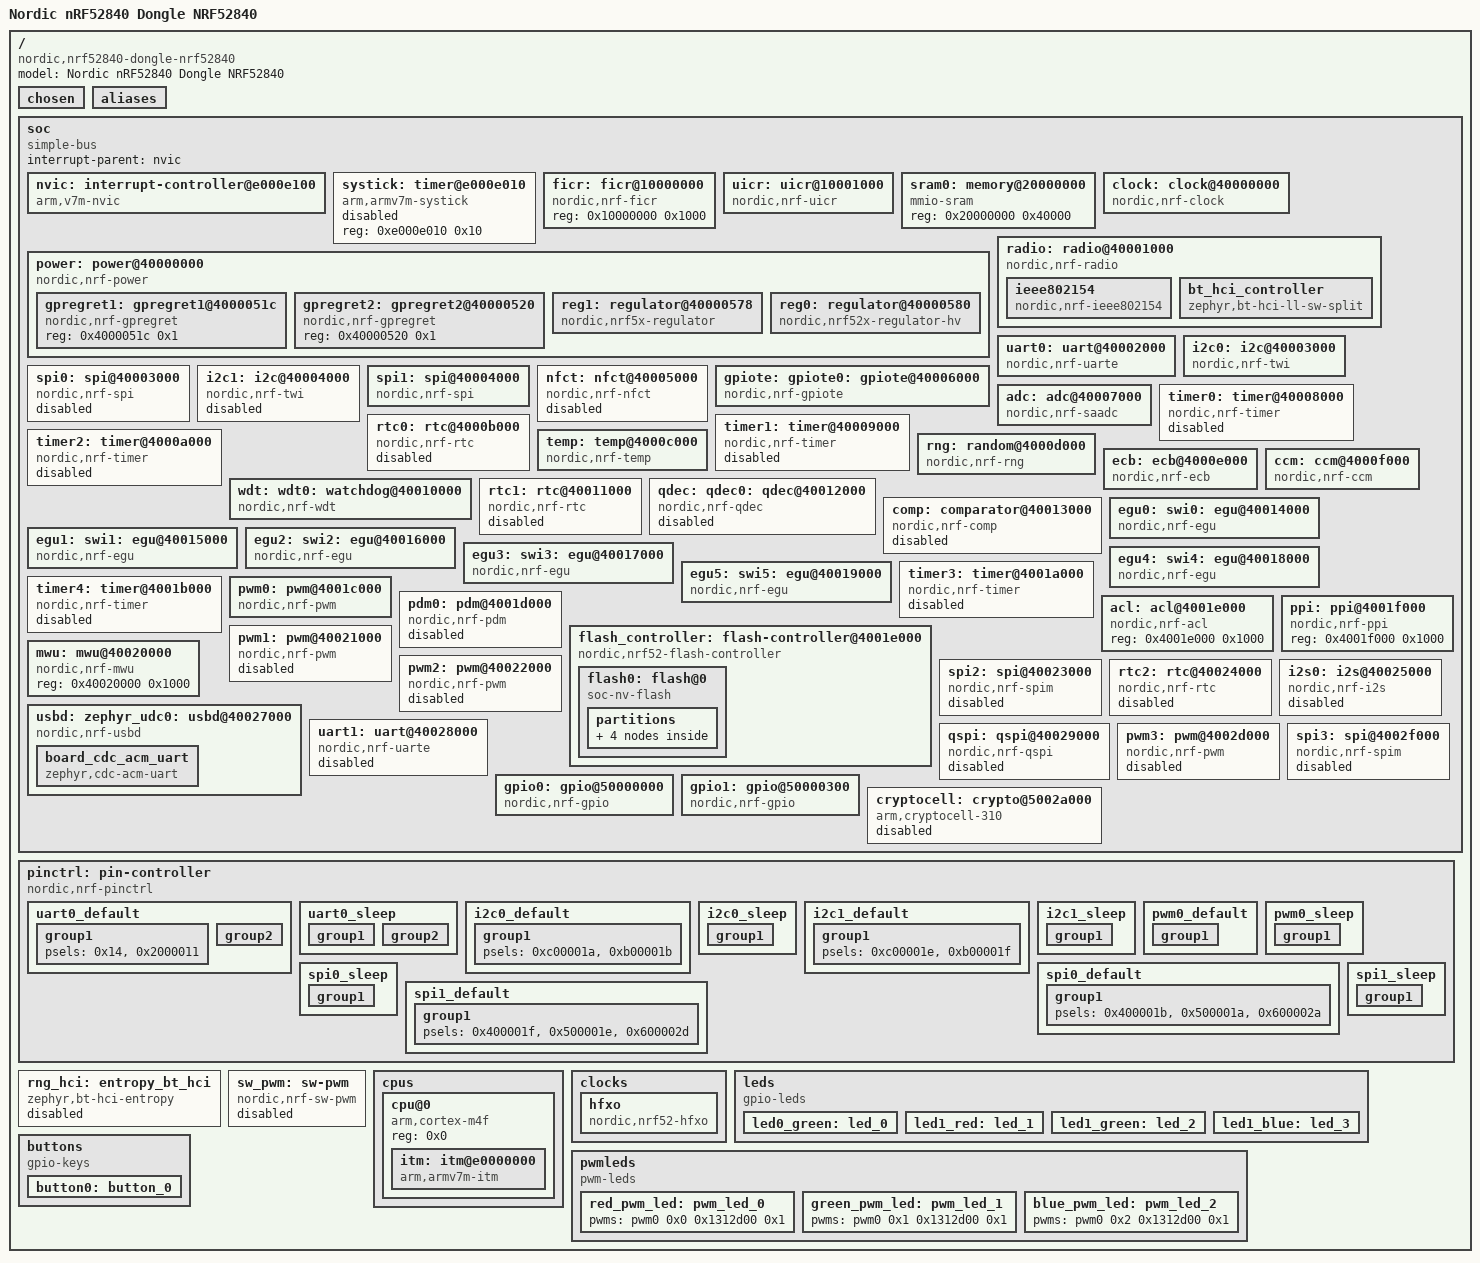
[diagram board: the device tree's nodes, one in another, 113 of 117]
/dts-v1/;

/* node '/' defined in zephyr/dts/common/skeleton.dtsi:9 */
/ {
	#address-cells = < 0x1 >;                       /* in zephyr/dts/common/skeleton.dtsi:10 */
	#size-cells = < 0x1 >;                          /* in zephyr/dts/common/skeleton.dtsi:11 */
	model = "Nordic nRF52840 Dongle NRF52840";      /* in zephyr/boards/nordic/nrf52840dongle/nrf52840dongle_nrf52840_common.dtsi:14 */
	compatible = "nordic,nrf52840-dongle-nrf52840"; /* in zephyr/boards/nordic/nrf52840dongle/nrf52840dongle_nrf52840_common.dtsi:15 */

	/* node '/chosen' defined in zephyr/dts/common/skeleton.dtsi:13 */
	chosen {
		zephyr,bt-hci = &bt_hci_controller;          /* in zephyr/dts/arm/nordic/nrf52840.dtsi:14 */
		zephyr,entropy = &rng;                       /* in zephyr/dts/arm/nordic/nrf52840.dtsi:15 */
		zephyr,flash-controller = &flash_controller; /* in zephyr/dts/arm/nordic/nrf52840.dtsi:16 */
		zephyr,sram = &sram0;                        /* in zephyr/boards/nordic/nrf52840dongle/nrf52840dongle_nrf52840_common.dtsi:18 */
		zephyr,flash = &flash0;                      /* in zephyr/boards/nordic/nrf52840dongle/nrf52840dongle_nrf52840_common.dtsi:19 */
		zephyr,code-partition = &slot0_partition;    /* in zephyr/boards/nordic/nrf52840dongle/nrf52840dongle_nrf52840_common.dtsi:20 */
		zephyr,ieee802154 = &ieee802154;             /* in zephyr/boards/nordic/nrf52840dongle/nrf52840dongle_nrf52840_common.dtsi:21 */
		zephyr,console = &board_cdc_acm_uart;        /* in zephyr/boards/common/usb/cdc_acm_serial.dtsi:9 */
		zephyr,shell-uart = &board_cdc_acm_uart;     /* in zephyr/boards/common/usb/cdc_acm_serial.dtsi:10 */
		zephyr,uart-mcumgr = &board_cdc_acm_uart;    /* in zephyr/boards/common/usb/cdc_acm_serial.dtsi:11 */
		zephyr,bt-mon-uart = &board_cdc_acm_uart;    /* in zephyr/boards/common/usb/cdc_acm_serial.dtsi:12 */
		zephyr,bt-c2h-uart = &board_cdc_acm_uart;    /* in zephyr/boards/common/usb/cdc_acm_serial.dtsi:13 */
	};

	/* node '/aliases' defined in zephyr/dts/common/skeleton.dtsi:15 */
	aliases {
		sw0 = &button0;                 /* in zephyr/boards/nordic/nrf52840dongle/nrf52840dongle_nrf52840_common.dtsi:76 */
		led0 = &led0_green;             /* in zephyr/boards/nordic/nrf52840dongle/nrf52840dongle_nrf52840_common.dtsi:77 */
		led1 = &led1_red;               /* in zephyr/boards/nordic/nrf52840dongle/nrf52840dongle_nrf52840_common.dtsi:78 */
		led2 = &led1_green;             /* in zephyr/boards/nordic/nrf52840dongle/nrf52840dongle_nrf52840_common.dtsi:79 */
		led3 = &led1_blue;              /* in zephyr/boards/nordic/nrf52840dongle/nrf52840dongle_nrf52840_common.dtsi:80 */
		led0-green = &led0_green;       /* in zephyr/boards/nordic/nrf52840dongle/nrf52840dongle_nrf52840_common.dtsi:81 */
		led1-red = &led1_red;           /* in zephyr/boards/nordic/nrf52840dongle/nrf52840dongle_nrf52840_common.dtsi:82 */
		led1-green = &led1_green;       /* in zephyr/boards/nordic/nrf52840dongle/nrf52840dongle_nrf52840_common.dtsi:83 */
		led1-blue = &led1_blue;         /* in zephyr/boards/nordic/nrf52840dongle/nrf52840dongle_nrf52840_common.dtsi:84 */
		pwm-led0 = &red_pwm_led;        /* in zephyr/boards/nordic/nrf52840dongle/nrf52840dongle_nrf52840_common.dtsi:85 */
		pwm-led1 = &green_pwm_led;      /* in zephyr/boards/nordic/nrf52840dongle/nrf52840dongle_nrf52840_common.dtsi:86 */
		pwm-led2 = &blue_pwm_led;       /* in zephyr/boards/nordic/nrf52840dongle/nrf52840dongle_nrf52840_common.dtsi:87 */
		red-pwm-led = &red_pwm_led;     /* in zephyr/boards/nordic/nrf52840dongle/nrf52840dongle_nrf52840_common.dtsi:88 */
		green-pwm-led = &green_pwm_led; /* in zephyr/boards/nordic/nrf52840dongle/nrf52840dongle_nrf52840_common.dtsi:89 */
		blue-pwm-led = &blue_pwm_led;   /* in zephyr/boards/nordic/nrf52840dongle/nrf52840dongle_nrf52840_common.dtsi:90 */
		mcuboot-button0 = &button0;     /* in zephyr/boards/nordic/nrf52840dongle/nrf52840dongle_nrf52840_common.dtsi:91 */
		mcuboot-led0 = &led0_green;     /* in zephyr/boards/nordic/nrf52840dongle/nrf52840dongle_nrf52840_common.dtsi:92 */
		watchdog0 = &wdt0;              /* in zephyr/boards/nordic/nrf52840dongle/nrf52840dongle_nrf52840_common.dtsi:93 */
	};

	/* node '/soc' defined in zephyr/dts/arm/armv7-m.dtsi:6 */
	soc {
		#address-cells = < 0x1 >;     /* in zephyr/dts/arm/armv7-m.dtsi:7 */
		#size-cells = < 0x1 >;        /* in zephyr/dts/arm/armv7-m.dtsi:8 */
		interrupt-parent = < &nvic >; /* in zephyr/dts/arm/armv7-m.dtsi:10 */
		ranges;                       /* in zephyr/dts/arm/armv7-m.dtsi:11 */
		compatible = "simple-bus";    /* in zephyr/dts/arm/nordic/nrf52840.dtsi:48 */

		/* node '/soc/interrupt-controller@e000e100' defined in zephyr/dts/arm/armv7-m.dtsi:13 */
		nvic: interrupt-controller@e000e100 {
			#address-cells = < 0x1 >;            /* in zephyr/dts/arm/armv7-m.dtsi:14 */
			compatible = "arm,v7m-nvic";         /* in zephyr/dts/arm/armv7-m.dtsi:15 */
			reg = < 0xe000e100 0xc00 >;          /* in zephyr/dts/arm/armv7-m.dtsi:16 */
			interrupt-controller;                /* in zephyr/dts/arm/armv7-m.dtsi:17 */
			#interrupt-cells = < 0x2 >;          /* in zephyr/dts/arm/armv7-m.dtsi:18 */
			arm,num-irq-priority-bits = < 0x3 >; /* in zephyr/dts/arm/nordic/nrf52840.dtsi:598 */
			phandle = < 0x1 >;                   /* in zephyr/dts/arm/armv7-m.dtsi:10 */
		};

		/* node '/soc/timer@e000e010' defined in zephyr/dts/arm/armv7-m.dtsi:21 */
		systick: timer@e000e010 {
			compatible = "arm,armv7m-systick"; /* in zephyr/dts/arm/armv7-m.dtsi:22 */
			reg = < 0xe000e010 0x10 >;         /* in zephyr/dts/arm/armv7-m.dtsi:23 */
			status = "disabled";               /* in zephyr/dts/arm/nordic/nrf52840.dtsi:603 */
		};

		/* node '/soc/ficr@10000000' defined in zephyr/dts/arm/nordic/nrf52840.dtsi:50 */
		ficr: ficr@10000000 {
			compatible = "nordic,nrf-ficr"; /* in zephyr/dts/arm/nordic/nrf52840.dtsi:51 */
			reg = < 0x10000000 0x1000 >;    /* in zephyr/dts/arm/nordic/nrf52840.dtsi:52 */
			#nordic,ficr-cells = < 0x1 >;   /* in zephyr/dts/arm/nordic/nrf52840.dtsi:53 */
			status = "okay";                /* in zephyr/dts/arm/nordic/nrf52840.dtsi:54 */
		};

		/* node '/soc/uicr@10001000' defined in zephyr/dts/arm/nordic/nrf52840.dtsi:57 */
		uicr: uicr@10001000 {
			compatible = "nordic,nrf-uicr";     /* in zephyr/dts/arm/nordic/nrf52840.dtsi:58 */
			reg = < 0x10001000 0x1000 >;        /* in zephyr/dts/arm/nordic/nrf52840.dtsi:59 */
			ranges = < 0x0 0x10001000 0x1000 >; /* in zephyr/dts/arm/nordic/nrf52840.dtsi:60 */
			status = "okay";                    /* in zephyr/dts/arm/nordic/nrf52840.dtsi:61 */
			#address-cells = < 0x1 >;           /* in zephyr/dts/arm/nordic/nrf52840.dtsi:62 */
			#size-cells = < 0x1 >;              /* in zephyr/dts/arm/nordic/nrf52840.dtsi:63 */
			nfct-pins-as-gpios;                 /* in zephyr/boards/nordic/nrf52840dongle/nrf52840dongle_nrf52840_common.dtsi:114 */
			gpio-as-nreset;                     /* in zephyr/boards/nordic/nrf52840dongle/nrf52840dongle_nrf52840_common.dtsi:115 */
		};

		/* node '/soc/memory@20000000' defined in zephyr/dts/arm/nordic/nrf52840.dtsi:66 */
		sram0: memory@20000000 {
			compatible = "mmio-sram";            /* in zephyr/dts/arm/nordic/nrf52840.dtsi:67 */
			reg = < 0x20000000 0x40000 >;        /* in zephyr/dts/arm/nordic/nrf52840.dtsi:68 */
			ranges = < 0x0 0x20000000 0x40000 >; /* in zephyr/dts/arm/nordic/nrf52840.dtsi:69 */
			#address-cells = < 0x1 >;            /* in zephyr/dts/arm/nordic/nrf52840.dtsi:70 */
			#size-cells = < 0x1 >;               /* in zephyr/dts/arm/nordic/nrf52840.dtsi:71 */
		};

		/* node '/soc/clock@40000000' defined in zephyr/dts/arm/nordic/nrf52840.dtsi:74 */
		clock: clock@40000000 {
			compatible = "nordic,nrf-clock"; /* in zephyr/dts/arm/nordic/nrf52840.dtsi:75 */
			reg = < 0x40000000 0x1000 >;     /* in zephyr/dts/arm/nordic/nrf52840.dtsi:76 */
			interrupts = < 0x0 0x1 >;        /* in zephyr/dts/arm/nordic/nrf52840.dtsi:77 */
			status = "okay";                 /* in zephyr/dts/arm/nordic/nrf52840.dtsi:78 */
		};

		/* node '/soc/power@40000000' defined in zephyr/dts/arm/nordic/nrf52840.dtsi:81 */
		power: power@40000000 {
			compatible = "nordic,nrf-power"; /* in zephyr/dts/arm/nordic/nrf52840.dtsi:82 */
			reg = < 0x40000000 0x1000 >;     /* in zephyr/dts/arm/nordic/nrf52840.dtsi:83 */
			interrupts = < 0x0 0x1 >;        /* in zephyr/dts/arm/nordic/nrf52840.dtsi:84 */
			status = "okay";                 /* in zephyr/dts/arm/nordic/nrf52840.dtsi:85 */
			#address-cells = < 0x1 >;        /* in zephyr/dts/arm/nordic/nrf52840.dtsi:86 */
			#size-cells = < 0x1 >;           /* in zephyr/dts/arm/nordic/nrf52840.dtsi:87 */

			/* node '/soc/power@40000000/gpregret1@4000051c' defined in zephyr/dts/arm/nordic/nrf52840.dtsi:89 */
			gpregret1: gpregret1@4000051c {
				#address-cells = < 0x1 >;           /* in zephyr/dts/arm/nordic/nrf52840.dtsi:90 */
				#size-cells = < 0x1 >;              /* in zephyr/dts/arm/nordic/nrf52840.dtsi:91 */
				compatible = "nordic,nrf-gpregret"; /* in zephyr/dts/arm/nordic/nrf52840.dtsi:92 */
				reg = < 0x4000051c 0x1 >;           /* in zephyr/dts/arm/nordic/nrf52840.dtsi:93 */
				status = "okay";                    /* in zephyr/dts/arm/nordic/nrf52840.dtsi:94 */
			};

			/* node '/soc/power@40000000/gpregret2@40000520' defined in zephyr/dts/arm/nordic/nrf52840.dtsi:97 */
			gpregret2: gpregret2@40000520 {
				#address-cells = < 0x1 >;           /* in zephyr/dts/arm/nordic/nrf52840.dtsi:98 */
				#size-cells = < 0x1 >;              /* in zephyr/dts/arm/nordic/nrf52840.dtsi:99 */
				compatible = "nordic,nrf-gpregret"; /* in zephyr/dts/arm/nordic/nrf52840.dtsi:100 */
				reg = < 0x40000520 0x1 >;           /* in zephyr/dts/arm/nordic/nrf52840.dtsi:101 */
				status = "okay";                    /* in zephyr/dts/arm/nordic/nrf52840.dtsi:102 */
			};

			/* node '/soc/power@40000000/regulator@40000578' defined in zephyr/dts/arm/nordic/nrf52840.dtsi:105 */
			reg1: regulator@40000578 {
				compatible = "nordic,nrf5x-regulator"; /* in zephyr/dts/arm/nordic/nrf52840.dtsi:106 */
				reg = < 0x40000578 0x1 >;              /* in zephyr/dts/arm/nordic/nrf52840.dtsi:107 */
				regulator-name = "REG1";               /* in zephyr/dts/arm/nordic/nrf52840.dtsi:108 */
				regulator-initial-mode = < 0x1 >;      /* in zephyr/boards/nordic/nrf52840dongle/nrf52840dongle_nrf52840_common.dtsi:102 */
			};

			/* node '/soc/power@40000000/regulator@40000580' defined in zephyr/dts/arm/nordic/nrf52840_qiaa.dtsi:11 */
			reg0: regulator@40000580 {
				compatible = "nordic,nrf52x-regulator-hv"; /* in zephyr/dts/arm/nordic/nrf52840_qiaa.dtsi:12 */
				reg = < 0x40000580 0x1 >;                  /* in zephyr/dts/arm/nordic/nrf52840_qiaa.dtsi:13 */
				regulator-name = "REG0";                   /* in zephyr/dts/arm/nordic/nrf52840_qiaa.dtsi:14 */
				status = "okay";                           /* in zephyr/boards/nordic/nrf52840dongle/nrf52840dongle_nrf52840_common.dtsi:98 */
			};
		};

		/* node '/soc/radio@40001000' defined in zephyr/dts/arm/nordic/nrf52840.dtsi:113 */
		radio: radio@40001000 {
			compatible = "nordic,nrf-radio"; /* in zephyr/dts/arm/nordic/nrf52840.dtsi:114 */
			reg = < 0x40001000 0x1000 >;     /* in zephyr/dts/arm/nordic/nrf52840.dtsi:115 */
			interrupts = < 0x1 0x1 >;        /* in zephyr/dts/arm/nordic/nrf52840.dtsi:116 */
			status = "okay";                 /* in zephyr/dts/arm/nordic/nrf52840.dtsi:117 */
			ieee802154-supported;            /* in zephyr/dts/arm/nordic/nrf52840.dtsi:118 */
			ble-2mbps-supported;             /* in zephyr/dts/arm/nordic/nrf52840.dtsi:119 */
			ble-coded-phy-supported;         /* in zephyr/dts/arm/nordic/nrf52840.dtsi:120 */
			radio-tx-high-power-supported;   /* in zephyr/dts/arm/nordic/nrf52840.dtsi:121 */

			/* node '/soc/radio@40001000/ieee802154' defined in zephyr/dts/arm/nordic/nrf52840.dtsi:123 */
			ieee802154: ieee802154 {
				compatible = "nordic,nrf-ieee802154"; /* in zephyr/dts/arm/nordic/nrf52840.dtsi:124 */
				status = "okay";                      /* in zephyr/boards/nordic/nrf52840dongle/nrf52840dongle_nrf52840_common.dtsi:181 */
			};

			/* node '/soc/radio@40001000/bt_hci_controller' defined in zephyr/dts/arm/nordic/nrf52840.dtsi:131 */
			bt_hci_controller: bt_hci_controller {
				compatible = "zephyr,bt-hci-ll-sw-split"; /* in zephyr/dts/arm/nordic/nrf52840.dtsi:132 */
				status = "okay";                          /* in zephyr/dts/arm/nordic/nrf52840.dtsi:133 */
			};
		};

		/* node '/soc/uart@40002000' defined in zephyr/dts/arm/nordic/nrf52840.dtsi:137 */
		uart0: uart@40002000 {
			reg = < 0x40002000 0x1000 >;     /* in zephyr/dts/arm/nordic/nrf52840.dtsi:141 */
			interrupts = < 0x2 0x1 >;        /* in zephyr/dts/arm/nordic/nrf52840.dtsi:142 */
			compatible = "nordic,nrf-uarte"; /* in zephyr/boards/nordic/nrf52840dongle/nrf52840dongle_nrf52840_common.dtsi:127 */
			status = "okay";                 /* in zephyr/boards/nordic/nrf52840dongle/nrf52840dongle_nrf52840_common.dtsi:128 */
			current-speed = < 0x1c200 >;     /* in zephyr/boards/nordic/nrf52840dongle/nrf52840dongle_nrf52840_common.dtsi:129 */
			pinctrl-0 = < &uart0_default >;  /* in zephyr/boards/nordic/nrf52840dongle/nrf52840dongle_nrf52840_common.dtsi:130 */
			pinctrl-1 = < &uart0_sleep >;    /* in zephyr/boards/nordic/nrf52840dongle/nrf52840dongle_nrf52840_common.dtsi:131 */
			pinctrl-names = "default",
			                "sleep";         /* in zephyr/boards/nordic/nrf52840dongle/nrf52840dongle_nrf52840_common.dtsi:132 */
		};

		/* node '/soc/i2c@40003000' defined in zephyr/dts/arm/nordic/nrf52840.dtsi:146 */
		i2c0: i2c@40003000 {
			#address-cells = < 0x1 >;       /* in zephyr/dts/arm/nordic/nrf52840.dtsi:155 */
			#size-cells = < 0x0 >;          /* in zephyr/dts/arm/nordic/nrf52840.dtsi:156 */
			reg = < 0x40003000 0x1000 >;    /* in zephyr/dts/arm/nordic/nrf52840.dtsi:157 */
			interrupts = < 0x3 0x1 >;       /* in zephyr/dts/arm/nordic/nrf52840.dtsi:158 */
			easydma-maxcnt-bits = < 0x10 >; /* in zephyr/dts/arm/nordic/nrf52840.dtsi:159 */
			zephyr,pm-device-runtime-auto;  /* in zephyr/dts/arm/nordic/nrf52840.dtsi:161 */
			compatible = "nordic,nrf-twi";  /* in zephyr/boards/nordic/nrf52840dongle/nrf52840dongle_nrf52840_common.dtsi:136 */
			status = "okay";                /* in zephyr/boards/nordic/nrf52840dongle/nrf52840dongle_nrf52840_common.dtsi:137 */
			pinctrl-0 = < &i2c0_default >;  /* in zephyr/boards/nordic/nrf52840dongle/nrf52840dongle_nrf52840_common.dtsi:138 */
			pinctrl-1 = < &i2c0_sleep >;    /* in zephyr/boards/nordic/nrf52840dongle/nrf52840dongle_nrf52840_common.dtsi:139 */
			pinctrl-names = "default",
			                "sleep";        /* in zephyr/boards/nordic/nrf52840dongle/nrf52840dongle_nrf52840_common.dtsi:140 */
		};

		/* node '/soc/spi@40003000' defined in zephyr/dts/arm/nordic/nrf52840.dtsi:164 */
		spi0: spi@40003000 {
			#address-cells = < 0x1 >;       /* in zephyr/dts/arm/nordic/nrf52840.dtsi:173 */
			#size-cells = < 0x0 >;          /* in zephyr/dts/arm/nordic/nrf52840.dtsi:174 */
			reg = < 0x40003000 0x1000 >;    /* in zephyr/dts/arm/nordic/nrf52840.dtsi:175 */
			interrupts = < 0x3 0x1 >;       /* in zephyr/dts/arm/nordic/nrf52840.dtsi:176 */
			max-frequency = < 0x7a1200 >;   /* in zephyr/dts/arm/nordic/nrf52840.dtsi:177 */
			easydma-maxcnt-bits = < 0x10 >; /* in zephyr/dts/arm/nordic/nrf52840.dtsi:178 */
			status = "disabled";            /* in zephyr/dts/arm/nordic/nrf52840.dtsi:179 */
			compatible = "nordic,nrf-spi";  /* in zephyr/boards/nordic/nrf52840dongle/nrf52840dongle_nrf52840_common.dtsi:164 */
			pinctrl-0 = < &spi0_default >;  /* in zephyr/boards/nordic/nrf52840dongle/nrf52840dongle_nrf52840_common.dtsi:167 */
			pinctrl-1 = < &spi0_sleep >;    /* in zephyr/boards/nordic/nrf52840dongle/nrf52840dongle_nrf52840_common.dtsi:168 */
			pinctrl-names = "default",
			                "sleep";        /* in zephyr/boards/nordic/nrf52840dongle/nrf52840dongle_nrf52840_common.dtsi:169 */
		};

		/* node '/soc/i2c@40004000' defined in zephyr/dts/arm/nordic/nrf52840.dtsi:182 */
		i2c1: i2c@40004000 {
			#address-cells = < 0x1 >;       /* in zephyr/dts/arm/nordic/nrf52840.dtsi:191 */
			#size-cells = < 0x0 >;          /* in zephyr/dts/arm/nordic/nrf52840.dtsi:192 */
			reg = < 0x40004000 0x1000 >;    /* in zephyr/dts/arm/nordic/nrf52840.dtsi:193 */
			interrupts = < 0x4 0x1 >;       /* in zephyr/dts/arm/nordic/nrf52840.dtsi:194 */
			easydma-maxcnt-bits = < 0x10 >; /* in zephyr/dts/arm/nordic/nrf52840.dtsi:195 */
			status = "disabled";            /* in zephyr/dts/arm/nordic/nrf52840.dtsi:196 */
			zephyr,pm-device-runtime-auto;  /* in zephyr/dts/arm/nordic/nrf52840.dtsi:197 */
			compatible = "nordic,nrf-twi";  /* in zephyr/boards/nordic/nrf52840dongle/nrf52840dongle_nrf52840_common.dtsi:144 */
			pinctrl-0 = < &i2c1_default >;  /* in zephyr/boards/nordic/nrf52840dongle/nrf52840dongle_nrf52840_common.dtsi:147 */
			pinctrl-1 = < &i2c1_sleep >;    /* in zephyr/boards/nordic/nrf52840dongle/nrf52840dongle_nrf52840_common.dtsi:148 */
			pinctrl-names = "default",
			                "sleep";        /* in zephyr/boards/nordic/nrf52840dongle/nrf52840dongle_nrf52840_common.dtsi:149 */
		};

		/* node '/soc/spi@40004000' defined in zephyr/dts/arm/nordic/nrf52840.dtsi:200 */
		spi1: spi@40004000 {
			#address-cells = < 0x1 >;       /* in zephyr/dts/arm/nordic/nrf52840.dtsi:209 */
			#size-cells = < 0x0 >;          /* in zephyr/dts/arm/nordic/nrf52840.dtsi:210 */
			reg = < 0x40004000 0x1000 >;    /* in zephyr/dts/arm/nordic/nrf52840.dtsi:211 */
			interrupts = < 0x4 0x1 >;       /* in zephyr/dts/arm/nordic/nrf52840.dtsi:212 */
			max-frequency = < 0x7a1200 >;   /* in zephyr/dts/arm/nordic/nrf52840.dtsi:213 */
			easydma-maxcnt-bits = < 0x10 >; /* in zephyr/dts/arm/nordic/nrf52840.dtsi:214 */
			compatible = "nordic,nrf-spi";  /* in zephyr/boards/nordic/nrf52840dongle/nrf52840dongle_nrf52840_common.dtsi:173 */
			status = "okay";                /* in zephyr/boards/nordic/nrf52840dongle/nrf52840dongle_nrf52840_common.dtsi:174 */
			pinctrl-0 = < &spi1_default >;  /* in zephyr/boards/nordic/nrf52840dongle/nrf52840dongle_nrf52840_common.dtsi:175 */
			pinctrl-1 = < &spi1_sleep >;    /* in zephyr/boards/nordic/nrf52840dongle/nrf52840dongle_nrf52840_common.dtsi:176 */
			pinctrl-names = "default",
			                "sleep";        /* in zephyr/boards/nordic/nrf52840dongle/nrf52840dongle_nrf52840_common.dtsi:177 */
		};

		/* node '/soc/nfct@40005000' defined in zephyr/dts/arm/nordic/nrf52840.dtsi:218 */
		nfct: nfct@40005000 {
			compatible = "nordic,nrf-nfct"; /* in zephyr/dts/arm/nordic/nrf52840.dtsi:219 */
			reg = < 0x40005000 0x1000 >;    /* in zephyr/dts/arm/nordic/nrf52840.dtsi:220 */
			interrupts = < 0x5 0x1 >;       /* in zephyr/dts/arm/nordic/nrf52840.dtsi:221 */
			status = "disabled";            /* in zephyr/dts/arm/nordic/nrf52840.dtsi:222 */
		};

		/* node '/soc/gpiote@40006000' defined in zephyr/dts/arm/nordic/nrf52840.dtsi:225 */
		gpiote: gpiote0: gpiote@40006000 {
			compatible = "nordic,nrf-gpiote"; /* in zephyr/dts/arm/nordic/nrf52840.dtsi:226 */
			reg = < 0x40006000 0x1000 >;      /* in zephyr/dts/arm/nordic/nrf52840.dtsi:227 */
			interrupts = < 0x6 0x5 >;         /* in zephyr/dts/arm/nordic/nrf52840.dtsi:228 */
			instance = < 0x0 >;               /* in zephyr/dts/arm/nordic/nrf52840.dtsi:230 */
			status = "okay";                  /* in zephyr/boards/nordic/nrf52840dongle/nrf52840dongle_nrf52840_common.dtsi:110 */
			phandle = < 0xe >;                /* in zephyr/dts/arm/nordic/nrf52840.dtsi:572 */
		};

		/* node '/soc/adc@40007000' defined in zephyr/dts/arm/nordic/nrf52840.dtsi:233 */
		adc: adc@40007000 {
			compatible = "nordic,nrf-saadc"; /* in zephyr/dts/arm/nordic/nrf52840.dtsi:234 */
			reg = < 0x40007000 0x1000 >;     /* in zephyr/dts/arm/nordic/nrf52840.dtsi:235 */
			interrupts = < 0x7 0x1 >;        /* in zephyr/dts/arm/nordic/nrf52840.dtsi:236 */
			#io-channel-cells = < 0x1 >;     /* in zephyr/dts/arm/nordic/nrf52840.dtsi:238 */
			zephyr,pm-device-runtime-auto;   /* in zephyr/dts/arm/nordic/nrf52840.dtsi:239 */
			status = "okay";                 /* in zephyr/boards/nordic/nrf52840dongle/nrf52840dongle_nrf52840_common.dtsi:106 */
		};

		/* node '/soc/timer@40008000' defined in zephyr/dts/arm/nordic/nrf52840.dtsi:242 */
		timer0: timer@40008000 {
			compatible = "nordic,nrf-timer"; /* in zephyr/dts/arm/nordic/nrf52840.dtsi:243 */
			status = "disabled";             /* in zephyr/dts/arm/nordic/nrf52840.dtsi:244 */
			reg = < 0x40008000 0x1000 >;     /* in zephyr/dts/arm/nordic/nrf52840.dtsi:245 */
			cc-num = < 0x4 >;                /* in zephyr/dts/arm/nordic/nrf52840.dtsi:246 */
			max-bit-width = < 0x20 >;        /* in zephyr/dts/arm/nordic/nrf52840.dtsi:247 */
			interrupts = < 0x8 0x1 >;        /* in zephyr/dts/arm/nordic/nrf52840.dtsi:248 */
			prescaler = < 0x0 >;             /* in zephyr/dts/arm/nordic/nrf52840.dtsi:249 */
		};

		/* node '/soc/timer@40009000' defined in zephyr/dts/arm/nordic/nrf52840.dtsi:252 */
		timer1: timer@40009000 {
			compatible = "nordic,nrf-timer"; /* in zephyr/dts/arm/nordic/nrf52840.dtsi:253 */
			status = "disabled";             /* in zephyr/dts/arm/nordic/nrf52840.dtsi:254 */
			reg = < 0x40009000 0x1000 >;     /* in zephyr/dts/arm/nordic/nrf52840.dtsi:255 */
			cc-num = < 0x4 >;                /* in zephyr/dts/arm/nordic/nrf52840.dtsi:256 */
			max-bit-width = < 0x20 >;        /* in zephyr/dts/arm/nordic/nrf52840.dtsi:257 */
			interrupts = < 0x9 0x1 >;        /* in zephyr/dts/arm/nordic/nrf52840.dtsi:258 */
			prescaler = < 0x0 >;             /* in zephyr/dts/arm/nordic/nrf52840.dtsi:259 */
			phandle = < 0xf >;               /* in zephyr/dts/vendor/nordic/nrf_common.dtsi:42 */
		};

		/* node '/soc/timer@4000a000' defined in zephyr/dts/arm/nordic/nrf52840.dtsi:262 */
		timer2: timer@4000a000 {
			compatible = "nordic,nrf-timer"; /* in zephyr/dts/arm/nordic/nrf52840.dtsi:263 */
			status = "disabled";             /* in zephyr/dts/arm/nordic/nrf52840.dtsi:264 */
			reg = < 0x4000a000 0x1000 >;     /* in zephyr/dts/arm/nordic/nrf52840.dtsi:265 */
			cc-num = < 0x4 >;                /* in zephyr/dts/arm/nordic/nrf52840.dtsi:266 */
			max-bit-width = < 0x20 >;        /* in zephyr/dts/arm/nordic/nrf52840.dtsi:267 */
			interrupts = < 0xa 0x1 >;        /* in zephyr/dts/arm/nordic/nrf52840.dtsi:268 */
			prescaler = < 0x0 >;             /* in zephyr/dts/arm/nordic/nrf52840.dtsi:269 */
		};

		/* node '/soc/rtc@4000b000' defined in zephyr/dts/arm/nordic/nrf52840.dtsi:272 */
		rtc0: rtc@4000b000 {
			compatible = "nordic,nrf-rtc"; /* in zephyr/dts/arm/nordic/nrf52840.dtsi:273 */
			reg = < 0x4000b000 0x1000 >;   /* in zephyr/dts/arm/nordic/nrf52840.dtsi:274 */
			cc-num = < 0x3 >;              /* in zephyr/dts/arm/nordic/nrf52840.dtsi:275 */
			interrupts = < 0xb 0x1 >;      /* in zephyr/dts/arm/nordic/nrf52840.dtsi:276 */
			status = "disabled";           /* in zephyr/dts/arm/nordic/nrf52840.dtsi:277 */
			clock-frequency = < 0x8000 >;  /* in zephyr/dts/arm/nordic/nrf52840.dtsi:278 */
			prescaler = < 0x1 >;           /* in zephyr/dts/arm/nordic/nrf52840.dtsi:279 */
		};

		/* node '/soc/temp@4000c000' defined in zephyr/dts/arm/nordic/nrf52840.dtsi:282 */
		temp: temp@4000c000 {
			compatible = "nordic,nrf-temp"; /* in zephyr/dts/arm/nordic/nrf52840.dtsi:283 */
			reg = < 0x4000c000 0x1000 >;    /* in zephyr/dts/arm/nordic/nrf52840.dtsi:284 */
			interrupts = < 0xc 0x1 >;       /* in zephyr/dts/arm/nordic/nrf52840.dtsi:285 */
			status = "okay";                /* in zephyr/dts/arm/nordic/nrf52840.dtsi:286 */
		};

		/* node '/soc/random@4000d000' defined in zephyr/dts/arm/nordic/nrf52840.dtsi:289 */
		rng: random@4000d000 {
			compatible = "nordic,nrf-rng"; /* in zephyr/dts/arm/nordic/nrf52840.dtsi:290 */
			reg = < 0x4000d000 0x1000 >;   /* in zephyr/dts/arm/nordic/nrf52840.dtsi:291 */
			interrupts = < 0xd 0x1 >;      /* in zephyr/dts/arm/nordic/nrf52840.dtsi:292 */
			status = "okay";               /* in zephyr/dts/arm/nordic/nrf52840.dtsi:293 */
		};

		/* node '/soc/ecb@4000e000' defined in zephyr/dts/arm/nordic/nrf52840.dtsi:296 */
		ecb: ecb@4000e000 {
			compatible = "nordic,nrf-ecb"; /* in zephyr/dts/arm/nordic/nrf52840.dtsi:297 */
			reg = < 0x4000e000 0x1000 >;   /* in zephyr/dts/arm/nordic/nrf52840.dtsi:298 */
			interrupts = < 0xe 0x1 >;      /* in zephyr/dts/arm/nordic/nrf52840.dtsi:299 */
			status = "okay";               /* in zephyr/dts/arm/nordic/nrf52840.dtsi:300 */
		};

		/* node '/soc/ccm@4000f000' defined in zephyr/dts/arm/nordic/nrf52840.dtsi:303 */
		ccm: ccm@4000f000 {
			compatible = "nordic,nrf-ccm"; /* in zephyr/dts/arm/nordic/nrf52840.dtsi:304 */
			reg = < 0x4000f000 0x1000 >;   /* in zephyr/dts/arm/nordic/nrf52840.dtsi:305 */
			interrupts = < 0xf 0x1 >;      /* in zephyr/dts/arm/nordic/nrf52840.dtsi:306 */
			length-field-length-8-bits;    /* in zephyr/dts/arm/nordic/nrf52840.dtsi:307 */
			status = "okay";               /* in zephyr/dts/arm/nordic/nrf52840.dtsi:308 */
		};

		/* node '/soc/watchdog@40010000' defined in zephyr/dts/arm/nordic/nrf52840.dtsi:311 */
		wdt: wdt0: watchdog@40010000 {
			compatible = "nordic,nrf-wdt"; /* in zephyr/dts/arm/nordic/nrf52840.dtsi:312 */
			reg = < 0x40010000 0x1000 >;   /* in zephyr/dts/arm/nordic/nrf52840.dtsi:313 */
			interrupts = < 0x10 0x1 >;     /* in zephyr/dts/arm/nordic/nrf52840.dtsi:314 */
			status = "okay";               /* in zephyr/dts/arm/nordic/nrf52840.dtsi:315 */
		};

		/* node '/soc/rtc@40011000' defined in zephyr/dts/arm/nordic/nrf52840.dtsi:318 */
		rtc1: rtc@40011000 {
			compatible = "nordic,nrf-rtc"; /* in zephyr/dts/arm/nordic/nrf52840.dtsi:319 */
			reg = < 0x40011000 0x1000 >;   /* in zephyr/dts/arm/nordic/nrf52840.dtsi:320 */
			cc-num = < 0x4 >;              /* in zephyr/dts/arm/nordic/nrf52840.dtsi:321 */
			interrupts = < 0x11 0x1 >;     /* in zephyr/dts/arm/nordic/nrf52840.dtsi:322 */
			status = "disabled";           /* in zephyr/dts/arm/nordic/nrf52840.dtsi:323 */
			clock-frequency = < 0x8000 >;  /* in zephyr/dts/arm/nordic/nrf52840.dtsi:324 */
			prescaler = < 0x1 >;           /* in zephyr/dts/arm/nordic/nrf52840.dtsi:325 */
		};

		/* node '/soc/qdec@40012000' defined in zephyr/dts/arm/nordic/nrf52840.dtsi:328 */
		qdec: qdec0: qdec@40012000 {
			compatible = "nordic,nrf-qdec"; /* in zephyr/dts/arm/nordic/nrf52840.dtsi:329 */
			reg = < 0x40012000 0x1000 >;    /* in zephyr/dts/arm/nordic/nrf52840.dtsi:330 */
			interrupts = < 0x12 0x1 >;      /* in zephyr/dts/arm/nordic/nrf52840.dtsi:331 */
			status = "disabled";            /* in zephyr/dts/arm/nordic/nrf52840.dtsi:332 */
		};

		/* node '/soc/comparator@40013000' defined in zephyr/dts/arm/nordic/nrf52840.dtsi:335 */
		comp: comparator@40013000 {
			compatible = "nordic,nrf-comp"; /* in zephyr/dts/arm/nordic/nrf52840.dtsi:340 */
			reg = < 0x40013000 0x1000 >;    /* in zephyr/dts/arm/nordic/nrf52840.dtsi:341 */
			interrupts = < 0x13 0x1 >;      /* in zephyr/dts/arm/nordic/nrf52840.dtsi:342 */
			status = "disabled";            /* in zephyr/dts/arm/nordic/nrf52840.dtsi:343 */
		};

		/* node '/soc/egu@40014000' defined in zephyr/dts/arm/nordic/nrf52840.dtsi:346 */
		egu0: swi0: egu@40014000 {
			compatible = "nordic,nrf-egu",
			             "nordic,nrf-swi"; /* in zephyr/dts/arm/nordic/nrf52840.dtsi:347 */
			reg = < 0x40014000 0x1000 >;   /* in zephyr/dts/arm/nordic/nrf52840.dtsi:348 */
			interrupts = < 0x14 0x1 >;     /* in zephyr/dts/arm/nordic/nrf52840.dtsi:349 */
			status = "okay";               /* in zephyr/dts/arm/nordic/nrf52840.dtsi:350 */
		};

		/* node '/soc/egu@40015000' defined in zephyr/dts/arm/nordic/nrf52840.dtsi:353 */
		egu1: swi1: egu@40015000 {
			compatible = "nordic,nrf-egu",
			             "nordic,nrf-swi"; /* in zephyr/dts/arm/nordic/nrf52840.dtsi:354 */
			reg = < 0x40015000 0x1000 >;   /* in zephyr/dts/arm/nordic/nrf52840.dtsi:355 */
			interrupts = < 0x15 0x1 >;     /* in zephyr/dts/arm/nordic/nrf52840.dtsi:356 */
			status = "okay";               /* in zephyr/dts/arm/nordic/nrf52840.dtsi:357 */
		};

		/* node '/soc/egu@40016000' defined in zephyr/dts/arm/nordic/nrf52840.dtsi:360 */
		egu2: swi2: egu@40016000 {
			compatible = "nordic,nrf-egu",
			             "nordic,nrf-swi"; /* in zephyr/dts/arm/nordic/nrf52840.dtsi:361 */
			reg = < 0x40016000 0x1000 >;   /* in zephyr/dts/arm/nordic/nrf52840.dtsi:362 */
			interrupts = < 0x16 0x1 >;     /* in zephyr/dts/arm/nordic/nrf52840.dtsi:363 */
			status = "okay";               /* in zephyr/dts/arm/nordic/nrf52840.dtsi:364 */
		};

		/* node '/soc/egu@40017000' defined in zephyr/dts/arm/nordic/nrf52840.dtsi:367 */
		egu3: swi3: egu@40017000 {
			compatible = "nordic,nrf-egu",
			             "nordic,nrf-swi"; /* in zephyr/dts/arm/nordic/nrf52840.dtsi:368 */
			reg = < 0x40017000 0x1000 >;   /* in zephyr/dts/arm/nordic/nrf52840.dtsi:369 */
			interrupts = < 0x17 0x1 >;     /* in zephyr/dts/arm/nordic/nrf52840.dtsi:370 */
			status = "okay";               /* in zephyr/dts/arm/nordic/nrf52840.dtsi:371 */
		};

		/* node '/soc/egu@40018000' defined in zephyr/dts/arm/nordic/nrf52840.dtsi:374 */
		egu4: swi4: egu@40018000 {
			compatible = "nordic,nrf-egu",
			             "nordic,nrf-swi"; /* in zephyr/dts/arm/nordic/nrf52840.dtsi:375 */
			reg = < 0x40018000 0x1000 >;   /* in zephyr/dts/arm/nordic/nrf52840.dtsi:376 */
			interrupts = < 0x18 0x1 >;     /* in zephyr/dts/arm/nordic/nrf52840.dtsi:377 */
			status = "okay";               /* in zephyr/dts/arm/nordic/nrf52840.dtsi:378 */
		};

		/* node '/soc/egu@40019000' defined in zephyr/dts/arm/nordic/nrf52840.dtsi:381 */
		egu5: swi5: egu@40019000 {
			compatible = "nordic,nrf-egu",
			             "nordic,nrf-swi"; /* in zephyr/dts/arm/nordic/nrf52840.dtsi:382 */
			reg = < 0x40019000 0x1000 >;   /* in zephyr/dts/arm/nordic/nrf52840.dtsi:383 */
			interrupts = < 0x19 0x1 >;     /* in zephyr/dts/arm/nordic/nrf52840.dtsi:384 */
			status = "okay";               /* in zephyr/dts/arm/nordic/nrf52840.dtsi:385 */
		};

		/* node '/soc/timer@4001a000' defined in zephyr/dts/arm/nordic/nrf52840.dtsi:388 */
		timer3: timer@4001a000 {
			compatible = "nordic,nrf-timer"; /* in zephyr/dts/arm/nordic/nrf52840.dtsi:389 */
			status = "disabled";             /* in zephyr/dts/arm/nordic/nrf52840.dtsi:390 */
			reg = < 0x4001a000 0x1000 >;     /* in zephyr/dts/arm/nordic/nrf52840.dtsi:391 */
			cc-num = < 0x6 >;                /* in zephyr/dts/arm/nordic/nrf52840.dtsi:392 */
			max-bit-width = < 0x20 >;        /* in zephyr/dts/arm/nordic/nrf52840.dtsi:393 */
			interrupts = < 0x1a 0x1 >;       /* in zephyr/dts/arm/nordic/nrf52840.dtsi:394 */
			prescaler = < 0x0 >;             /* in zephyr/dts/arm/nordic/nrf52840.dtsi:395 */
		};

		/* node '/soc/timer@4001b000' defined in zephyr/dts/arm/nordic/nrf52840.dtsi:398 */
		timer4: timer@4001b000 {
			compatible = "nordic,nrf-timer"; /* in zephyr/dts/arm/nordic/nrf52840.dtsi:399 */
			status = "disabled";             /* in zephyr/dts/arm/nordic/nrf52840.dtsi:400 */
			reg = < 0x4001b000 0x1000 >;     /* in zephyr/dts/arm/nordic/nrf52840.dtsi:401 */
			cc-num = < 0x6 >;                /* in zephyr/dts/arm/nordic/nrf52840.dtsi:402 */
			max-bit-width = < 0x20 >;        /* in zephyr/dts/arm/nordic/nrf52840.dtsi:403 */
			interrupts = < 0x1b 0x1 >;       /* in zephyr/dts/arm/nordic/nrf52840.dtsi:404 */
			prescaler = < 0x0 >;             /* in zephyr/dts/arm/nordic/nrf52840.dtsi:405 */
		};

		/* node '/soc/pwm@4001c000' defined in zephyr/dts/arm/nordic/nrf52840.dtsi:408 */
		pwm0: pwm@4001c000 {
			compatible = "nordic,nrf-pwm"; /* in zephyr/dts/arm/nordic/nrf52840.dtsi:409 */
			reg = < 0x4001c000 0x1000 >;   /* in zephyr/dts/arm/nordic/nrf52840.dtsi:410 */
			interrupts = < 0x1c 0x1 >;     /* in zephyr/dts/arm/nordic/nrf52840.dtsi:411 */
			#pwm-cells = < 0x3 >;          /* in zephyr/dts/arm/nordic/nrf52840.dtsi:413 */
			status = "okay";               /* in zephyr/boards/nordic/nrf52840dongle/nrf52840dongle_nrf52840_common.dtsi:153 */
			pinctrl-0 = < &pwm0_default >; /* in zephyr/boards/nordic/nrf52840dongle/nrf52840dongle_nrf52840_common.dtsi:154 */
			pinctrl-1 = < &pwm0_sleep >;   /* in zephyr/boards/nordic/nrf52840dongle/nrf52840dongle_nrf52840_common.dtsi:155 */
			pinctrl-names = "default",
			                "sleep";       /* in zephyr/boards/nordic/nrf52840dongle/nrf52840dongle_nrf52840_common.dtsi:156 */
			phandle = < 0x12 >;            /* in zephyr/boards/nordic/nrf52840dongle/nrf52840dongle_nrf52840_common.dtsi:52 */
		};

		/* node '/soc/pdm@4001d000' defined in zephyr/dts/arm/nordic/nrf52840.dtsi:416 */
		pdm0: pdm@4001d000 {
			compatible = "nordic,nrf-pdm"; /* in zephyr/dts/arm/nordic/nrf52840.dtsi:417 */
			reg = < 0x4001d000 0x1000 >;   /* in zephyr/dts/arm/nordic/nrf52840.dtsi:418 */
			interrupts = < 0x1d 0x1 >;     /* in zephyr/dts/arm/nordic/nrf52840.dtsi:419 */
			status = "disabled";           /* in zephyr/dts/arm/nordic/nrf52840.dtsi:420 */
		};

		/* node '/soc/acl@4001e000' defined in zephyr/dts/arm/nordic/nrf52840.dtsi:423 */
		acl: acl@4001e000 {
			compatible = "nordic,nrf-acl"; /* in zephyr/dts/arm/nordic/nrf52840.dtsi:424 */
			reg = < 0x4001e000 0x1000 >;   /* in zephyr/dts/arm/nordic/nrf52840.dtsi:425 */
			status = "okay";               /* in zephyr/dts/arm/nordic/nrf52840.dtsi:426 */
		};

		/* node '/soc/flash-controller@4001e000' defined in zephyr/dts/arm/nordic/nrf52840.dtsi:429 */
		flash_controller: flash-controller@4001e000 {
			compatible = "nordic,nrf52-flash-controller"; /* in zephyr/dts/arm/nordic/nrf52840.dtsi:430 */
			reg = < 0x4001e000 0x1000 >;                  /* in zephyr/dts/arm/nordic/nrf52840.dtsi:431 */
			ranges;                                       /* in zephyr/dts/arm/nordic/nrf52840.dtsi:432 */
			partial-erase;                                /* in zephyr/dts/arm/nordic/nrf52840.dtsi:433 */
			#address-cells = < 0x1 >;                     /* in zephyr/dts/arm/nordic/nrf52840.dtsi:434 */
			#size-cells = < 0x1 >;                        /* in zephyr/dts/arm/nordic/nrf52840.dtsi:435 */

			/* node '/soc/flash-controller@4001e000/flash@0' defined in zephyr/dts/arm/nordic/nrf52840.dtsi:437 */
			flash0: flash@0 {
				compatible = "soc-nv-flash";   /* in zephyr/dts/arm/nordic/nrf52840.dtsi:438 */
				erase-block-size = < 0x1000 >; /* in zephyr/dts/arm/nordic/nrf52840.dtsi:439 */
				write-block-size = < 0x4 >;    /* in zephyr/dts/arm/nordic/nrf52840.dtsi:440 */
				reg = < 0x0 0x100000 >;        /* in zephyr/dts/arm/nordic/nrf52840.dtsi:441 */
				ranges = < 0x0 0x0 0x100000 >; /* in zephyr/dts/arm/nordic/nrf52840.dtsi:442 */
				status = "okay";               /* in zephyr/dts/arm/nordic/nrf52840.dtsi:443 */
				#address-cells = < 0x1 >;      /* in zephyr/dts/arm/nordic/nrf52840.dtsi:444 */
				#size-cells = < 0x1 >;         /* in zephyr/dts/arm/nordic/nrf52840.dtsi:445 */

				/* node '/soc/flash-controller@4001e000/flash@0/partitions' defined in zephyr/boards/nordic/nrf52840dongle/nrf52840dongle_nrf52840.dts:14 */
				partitions {
					ranges;                   /* in zephyr/boards/nordic/nrf52840dongle/nrf52840dongle_nrf52840.dts:15 */
					#address-cells = < 0x1 >; /* in zephyr/boards/nordic/nrf52840dongle/nrf52840dongle_nrf52840.dts:16 */
					#size-cells = < 0x1 >;    /* in zephyr/boards/nordic/nrf52840dongle/nrf52840dongle_nrf52840.dts:17 */

					/* node '/soc/flash-controller@4001e000/flash@0/partitions/partition@1000' defined in zephyr/boards/nordic/nrf52840dongle/nrf52840dongle_nrf52840.dts:23 */
					boot_partition: partition@1000 {
						compatible = "zephyr,mapped-partition"; /* in zephyr/boards/nordic/nrf52840dongle/nrf52840dongle_nrf52840.dts:24 */
						label = "mcuboot";                      /* in zephyr/boards/nordic/nrf52840dongle/nrf52840dongle_nrf52840.dts:25 */
						reg = < 0x1000 0xf000 >;                /* in zephyr/boards/nordic/nrf52840dongle/nrf52840dongle_nrf52840.dts:26 */
					};

					/* node '/soc/flash-controller@4001e000/flash@0/partitions/partition@10000' defined in zephyr/boards/nordic/nrf52840dongle/nrf52840dongle_nrf52840.dts:29 */
					slot0_partition: partition@10000 {
						compatible = "zephyr,mapped-partition"; /* in zephyr/boards/nordic/nrf52840dongle/nrf52840dongle_nrf52840.dts:30 */
						label = "image-0";                      /* in zephyr/boards/nordic/nrf52840dongle/nrf52840dongle_nrf52840.dts:31 */
						reg = < 0x10000 0x66000 >;              /* in zephyr/boards/nordic/nrf52840dongle/nrf52840dongle_nrf52840.dts:32 */
					};

					/* node '/soc/flash-controller@4001e000/flash@0/partitions/partition@76000' defined in zephyr/boards/nordic/nrf52840dongle/nrf52840dongle_nrf52840.dts:35 */
					slot1_partition: partition@76000 {
						compatible = "zephyr,mapped-partition"; /* in zephyr/boards/nordic/nrf52840dongle/nrf52840dongle_nrf52840.dts:36 */
						label = "image-1";                      /* in zephyr/boards/nordic/nrf52840dongle/nrf52840dongle_nrf52840.dts:37 */
						reg = < 0x76000 0x66000 >;              /* in zephyr/boards/nordic/nrf52840dongle/nrf52840dongle_nrf52840.dts:38 */
					};

					/* node '/soc/flash-controller@4001e000/flash@0/partitions/partition@dc000' defined in zephyr/boards/nordic/nrf52840dongle/nrf52840dongle_nrf52840.dts:41 */
					storage_partition: partition@dc000 {
						compatible = "zephyr,mapped-partition"; /* in zephyr/boards/nordic/nrf52840dongle/nrf52840dongle_nrf52840.dts:42 */
						label = "storage";                      /* in zephyr/boards/nordic/nrf52840dongle/nrf52840dongle_nrf52840.dts:43 */
						reg = < 0xdc000 0x4000 >;               /* in zephyr/boards/nordic/nrf52840dongle/nrf52840dongle_nrf52840.dts:44 */
					};
				};
			};
		};

		/* node '/soc/ppi@4001f000' defined in zephyr/dts/arm/nordic/nrf52840.dtsi:449 */
		ppi: ppi@4001f000 {
			compatible = "nordic,nrf-ppi"; /* in zephyr/dts/arm/nordic/nrf52840.dtsi:450 */
			reg = < 0x4001f000 0x1000 >;   /* in zephyr/dts/arm/nordic/nrf52840.dtsi:451 */
			status = "okay";               /* in zephyr/dts/arm/nordic/nrf52840.dtsi:452 */
		};

		/* node '/soc/mwu@40020000' defined in zephyr/dts/arm/nordic/nrf52840.dtsi:455 */
		mwu: mwu@40020000 {
			compatible = "nordic,nrf-mwu"; /* in zephyr/dts/arm/nordic/nrf52840.dtsi:456 */
			reg = < 0x40020000 0x1000 >;   /* in zephyr/dts/arm/nordic/nrf52840.dtsi:457 */
			status = "okay";               /* in zephyr/dts/arm/nordic/nrf52840.dtsi:458 */
		};

		/* node '/soc/pwm@40021000' defined in zephyr/dts/arm/nordic/nrf52840.dtsi:461 */
		pwm1: pwm@40021000 {
			compatible = "nordic,nrf-pwm"; /* in zephyr/dts/arm/nordic/nrf52840.dtsi:462 */
			reg = < 0x40021000 0x1000 >;   /* in zephyr/dts/arm/nordic/nrf52840.dtsi:463 */
			interrupts = < 0x21 0x1 >;     /* in zephyr/dts/arm/nordic/nrf52840.dtsi:464 */
			status = "disabled";           /* in zephyr/dts/arm/nordic/nrf52840.dtsi:465 */
			#pwm-cells = < 0x3 >;          /* in zephyr/dts/arm/nordic/nrf52840.dtsi:466 */
		};

		/* node '/soc/pwm@40022000' defined in zephyr/dts/arm/nordic/nrf52840.dtsi:469 */
		pwm2: pwm@40022000 {
			compatible = "nordic,nrf-pwm"; /* in zephyr/dts/arm/nordic/nrf52840.dtsi:470 */
			reg = < 0x40022000 0x1000 >;   /* in zephyr/dts/arm/nordic/nrf52840.dtsi:471 */
			interrupts = < 0x22 0x1 >;     /* in zephyr/dts/arm/nordic/nrf52840.dtsi:472 */
			status = "disabled";           /* in zephyr/dts/arm/nordic/nrf52840.dtsi:473 */
			#pwm-cells = < 0x3 >;          /* in zephyr/dts/arm/nordic/nrf52840.dtsi:474 */
		};

		/* node '/soc/spi@40023000' defined in zephyr/dts/arm/nordic/nrf52840.dtsi:477 */
		spi2: spi@40023000 {
			compatible = "nordic,nrf-spim"; /* in zephyr/dts/arm/nordic/nrf52840.dtsi:485 */
			#address-cells = < 0x1 >;       /* in zephyr/dts/arm/nordic/nrf52840.dtsi:486 */
			#size-cells = < 0x0 >;          /* in zephyr/dts/arm/nordic/nrf52840.dtsi:487 */
			reg = < 0x40023000 0x1000 >;    /* in zephyr/dts/arm/nordic/nrf52840.dtsi:488 */
			interrupts = < 0x23 0x1 >;      /* in zephyr/dts/arm/nordic/nrf52840.dtsi:489 */
			max-frequency = < 0x7a1200 >;   /* in zephyr/dts/arm/nordic/nrf52840.dtsi:490 */
			easydma-maxcnt-bits = < 0x10 >; /* in zephyr/dts/arm/nordic/nrf52840.dtsi:491 */
			status = "disabled";            /* in zephyr/dts/arm/nordic/nrf52840.dtsi:492 */
		};

		/* node '/soc/rtc@40024000' defined in zephyr/dts/arm/nordic/nrf52840.dtsi:495 */
		rtc2: rtc@40024000 {
			compatible = "nordic,nrf-rtc"; /* in zephyr/dts/arm/nordic/nrf52840.dtsi:496 */
			reg = < 0x40024000 0x1000 >;   /* in zephyr/dts/arm/nordic/nrf52840.dtsi:497 */
			cc-num = < 0x4 >;              /* in zephyr/dts/arm/nordic/nrf52840.dtsi:498 */
			interrupts = < 0x24 0x1 >;     /* in zephyr/dts/arm/nordic/nrf52840.dtsi:499 */
			status = "disabled";           /* in zephyr/dts/arm/nordic/nrf52840.dtsi:500 */
			clock-frequency = < 0x8000 >;  /* in zephyr/dts/arm/nordic/nrf52840.dtsi:501 */
			prescaler = < 0x1 >;           /* in zephyr/dts/arm/nordic/nrf52840.dtsi:502 */
		};

		/* node '/soc/i2s@40025000' defined in zephyr/dts/arm/nordic/nrf52840.dtsi:505 */
		i2s0: i2s@40025000 {
			compatible = "nordic,nrf-i2s"; /* in zephyr/dts/arm/nordic/nrf52840.dtsi:506 */
			#address-cells = < 0x1 >;      /* in zephyr/dts/arm/nordic/nrf52840.dtsi:507 */
			#size-cells = < 0x0 >;         /* in zephyr/dts/arm/nordic/nrf52840.dtsi:508 */
			reg = < 0x40025000 0x1000 >;   /* in zephyr/dts/arm/nordic/nrf52840.dtsi:509 */
			interrupts = < 0x25 0x1 >;     /* in zephyr/dts/arm/nordic/nrf52840.dtsi:510 */
			status = "disabled";           /* in zephyr/dts/arm/nordic/nrf52840.dtsi:511 */
		};

		/* node '/soc/usbd@40027000' defined in zephyr/dts/arm/nordic/nrf52840.dtsi:514 */
		usbd: zephyr_udc0: usbd@40027000 {
			reg = < 0x40027000 0x1000 >;    /* in zephyr/dts/arm/nordic/nrf52840.dtsi:516 */
			interrupts = < 0x27 0x1 >;      /* in zephyr/dts/arm/nordic/nrf52840.dtsi:517 */
			num-bidir-endpoints = < 0x1 >;  /* in zephyr/dts/arm/nordic/nrf52840.dtsi:518 */
			num-in-endpoints = < 0x7 >;     /* in zephyr/dts/arm/nordic/nrf52840.dtsi:519 */
			num-out-endpoints = < 0x7 >;    /* in zephyr/dts/arm/nordic/nrf52840.dtsi:520 */
			num-isoin-endpoints = < 0x1 >;  /* in zephyr/dts/arm/nordic/nrf52840.dtsi:521 */
			num-isoout-endpoints = < 0x1 >; /* in zephyr/dts/arm/nordic/nrf52840.dtsi:522 */
			compatible = "nordic,nrf-usbd"; /* in zephyr/boards/nordic/nrf52840dongle/nrf52840dongle_nrf52840_common.dtsi:185 */
			status = "okay";                /* in zephyr/boards/nordic/nrf52840dongle/nrf52840dongle_nrf52840_common.dtsi:186 */

			/* node '/soc/usbd@40027000/board_cdc_acm_uart' defined in zephyr/boards/common/usb/cdc_acm_serial.dtsi:18 */
			board_cdc_acm_uart: board_cdc_acm_uart {
				compatible = "zephyr,cdc-acm-uart"; /* in zephyr/boards/common/usb/cdc_acm_serial.dtsi:19 */
			};
		};

		/* node '/soc/uart@40028000' defined in zephyr/dts/arm/nordic/nrf52840.dtsi:526 */
		uart1: uart@40028000 {
			compatible = "nordic,nrf-uarte"; /* in zephyr/dts/arm/nordic/nrf52840.dtsi:527 */
			reg = < 0x40028000 0x1000 >;     /* in zephyr/dts/arm/nordic/nrf52840.dtsi:528 */
			interrupts = < 0x28 0x1 >;       /* in zephyr/dts/arm/nordic/nrf52840.dtsi:529 */
			status = "disabled";             /* in zephyr/dts/arm/nordic/nrf52840.dtsi:530 */
		};

		/* node '/soc/qspi@40029000' defined in zephyr/dts/arm/nordic/nrf52840.dtsi:533 */
		qspi: qspi@40029000 {
			compatible = "nordic,nrf-qspi"; /* in zephyr/dts/arm/nordic/nrf52840.dtsi:534 */
			#address-cells = < 0x1 >;       /* in zephyr/dts/arm/nordic/nrf52840.dtsi:535 */
			#size-cells = < 0x0 >;          /* in zephyr/dts/arm/nordic/nrf52840.dtsi:536 */
			reg = < 0x40029000 0x1000 >,
			      < 0x12000000 0x8000000 >; /* in zephyr/dts/arm/nordic/nrf52840.dtsi:537 */
			reg-names = "qspi",
			            "qspi_mm";          /* in zephyr/dts/arm/nordic/nrf52840.dtsi:538 */
			interrupts = < 0x29 0x1 >;      /* in zephyr/dts/arm/nordic/nrf52840.dtsi:539 */
			status = "disabled";            /* in zephyr/dts/arm/nordic/nrf52840.dtsi:540 */
		};

		/* node '/soc/pwm@4002d000' defined in zephyr/dts/arm/nordic/nrf52840.dtsi:543 */
		pwm3: pwm@4002d000 {
			compatible = "nordic,nrf-pwm"; /* in zephyr/dts/arm/nordic/nrf52840.dtsi:544 */
			reg = < 0x4002d000 0x1000 >;   /* in zephyr/dts/arm/nordic/nrf52840.dtsi:545 */
			interrupts = < 0x2d 0x1 >;     /* in zephyr/dts/arm/nordic/nrf52840.dtsi:546 */
			status = "disabled";           /* in zephyr/dts/arm/nordic/nrf52840.dtsi:547 */
			#pwm-cells = < 0x3 >;          /* in zephyr/dts/arm/nordic/nrf52840.dtsi:548 */
		};

		/* node '/soc/spi@4002f000' defined in zephyr/dts/arm/nordic/nrf52840.dtsi:551 */
		spi3: spi@4002f000 {
			compatible = "nordic,nrf-spim"; /* in zephyr/dts/arm/nordic/nrf52840.dtsi:552 */
			#address-cells = < 0x1 >;       /* in zephyr/dts/arm/nordic/nrf52840.dtsi:553 */
			#size-cells = < 0x0 >;          /* in zephyr/dts/arm/nordic/nrf52840.dtsi:554 */
			reg = < 0x4002f000 0x1000 >;    /* in zephyr/dts/arm/nordic/nrf52840.dtsi:555 */
			interrupts = < 0x2f 0x1 >;      /* in zephyr/dts/arm/nordic/nrf52840.dtsi:556 */
			max-frequency = < 0x1e84800 >;  /* in zephyr/dts/arm/nordic/nrf52840.dtsi:557 */
			easydma-maxcnt-bits = < 0x10 >; /* in zephyr/dts/arm/nordic/nrf52840.dtsi:558 */
			rx-delay-supported;             /* in zephyr/dts/arm/nordic/nrf52840.dtsi:559 */
			rx-delay = < 0x2 >;             /* in zephyr/dts/arm/nordic/nrf52840.dtsi:560 */
			status = "disabled";            /* in zephyr/dts/arm/nordic/nrf52840.dtsi:561 */
		};

		/* node '/soc/gpio@50000000' defined in zephyr/dts/arm/nordic/nrf52840.dtsi:564 */
		gpio0: gpio@50000000 {
			compatible = "nordic,nrf-gpio";              /* in zephyr/dts/arm/nordic/nrf52840.dtsi:565 */
			gpio-controller;                             /* in zephyr/dts/arm/nordic/nrf52840.dtsi:566 */
			reg = < 0x50000000 0x200 0x50000500 0x300 >; /* in zephyr/dts/arm/nordic/nrf52840.dtsi:567 */
			#gpio-cells = < 0x2 >;                       /* in zephyr/dts/arm/nordic/nrf52840.dtsi:569 */
			port = < 0x0 >;                              /* in zephyr/dts/arm/nordic/nrf52840.dtsi:571 */
			gpiote-instance = < &gpiote >;               /* in zephyr/dts/arm/nordic/nrf52840.dtsi:572 */
			status = "okay";                             /* in zephyr/boards/nordic/nrf52840dongle/nrf52840dongle_nrf52840_common.dtsi:119 */
			phandle = < 0x10 >;                          /* in zephyr/boards/nordic/nrf52840dongle/nrf52840dongle_nrf52840_common.dtsi:28 */
		};

		/* node '/soc/gpio@50000300' defined in zephyr/dts/arm/nordic/nrf52840.dtsi:575 */
		gpio1: gpio@50000300 {
			compatible = "nordic,nrf-gpio";              /* in zephyr/dts/arm/nordic/nrf52840.dtsi:576 */
			gpio-controller;                             /* in zephyr/dts/arm/nordic/nrf52840.dtsi:577 */
			reg = < 0x50000300 0x200 0x50000800 0x300 >; /* in zephyr/dts/arm/nordic/nrf52840.dtsi:578 */
			#gpio-cells = < 0x2 >;                       /* in zephyr/dts/arm/nordic/nrf52840.dtsi:580 */
			ngpios = < 0x10 >;                           /* in zephyr/dts/arm/nordic/nrf52840.dtsi:581 */
			port = < 0x1 >;                              /* in zephyr/dts/arm/nordic/nrf52840.dtsi:583 */
			gpiote-instance = < &gpiote >;               /* in zephyr/dts/arm/nordic/nrf52840.dtsi:584 */
			status = "okay";                             /* in zephyr/boards/nordic/nrf52840dongle/nrf52840dongle_nrf52840_common.dtsi:123 */
			phandle = < 0x11 >;                          /* in zephyr/boards/nordic/nrf52840dongle/nrf52840dongle_nrf52840_common.dtsi:38 */
		};

		/* node '/soc/crypto@5002a000' defined in zephyr/dts/arm/nordic/nrf52840.dtsi:587 */
		cryptocell: crypto@5002a000 {
			compatible = "arm,cryptocell-310"; /* in zephyr/dts/arm/nordic/nrf52840.dtsi:588 */
			reg = < 0x5002a000 0x1000 >,
			      < 0x5002b000 0x1000 >;       /* in zephyr/dts/arm/nordic/nrf52840.dtsi:589 */
			reg-names = "wrapper",
			            "core";                /* in zephyr/dts/arm/nordic/nrf52840.dtsi:590 */
			interrupts = < 0x2a 0x1 >;         /* in zephyr/dts/arm/nordic/nrf52840.dtsi:591 */
			status = "disabled";               /* in zephyr/dts/arm/nordic/nrf52840.dtsi:592 */
		};
	};

	/* node '/pin-controller' defined in zephyr/dts/vendor/nordic/nrf_common.dtsi:26 */
	pinctrl: pin-controller {
		compatible = "nordic,nrf-pinctrl"; /* in zephyr/dts/vendor/nordic/nrf_common.dtsi:31 */

		/* node '/pin-controller/uart0_default' defined in zephyr/boards/nordic/nrf52840dongle/nrf52840dongle_nrf52840-pinctrl.dtsi:7 */
		uart0_default: uart0_default {
			phandle = < 0x2 >; /* in zephyr/boards/nordic/nrf52840dongle/nrf52840dongle_nrf52840_common.dtsi:130 */

			/* node '/pin-controller/uart0_default/group1' defined in zephyr/boards/nordic/nrf52840dongle/nrf52840dongle_nrf52840-pinctrl.dtsi:8 */
			group1 {
				psels = < 0x14 >,
				        < 0x2000011 >; /* in zephyr/boards/nordic/nrf52840dongle/nrf52840dongle_nrf52840-pinctrl.dtsi:9 */
			};

			/* node '/pin-controller/uart0_default/group2' defined in zephyr/boards/nordic/nrf52840dongle/nrf52840dongle_nrf52840-pinctrl.dtsi:13 */
			group2 {
				psels = < 0x1000018 >,
				        < 0x3000016 >; /* in zephyr/boards/nordic/nrf52840dongle/nrf52840dongle_nrf52840-pinctrl.dtsi:14 */
				bias-pull-up;          /* in zephyr/boards/nordic/nrf52840dongle/nrf52840dongle_nrf52840-pinctrl.dtsi:16 */
			};
		};

		/* node '/pin-controller/uart0_sleep' defined in zephyr/boards/nordic/nrf52840dongle/nrf52840dongle_nrf52840-pinctrl.dtsi:20 */
		uart0_sleep: uart0_sleep {
			phandle = < 0x3 >; /* in zephyr/boards/nordic/nrf52840dongle/nrf52840dongle_nrf52840_common.dtsi:131 */

			/* node '/pin-controller/uart0_sleep/group1' defined in zephyr/boards/nordic/nrf52840dongle/nrf52840dongle_nrf52840-pinctrl.dtsi:21 */
			group1 {
				psels = < 0x1000018 >,
				        < 0x2000011 >,
				        < 0x3000016 >; /* in zephyr/boards/nordic/nrf52840dongle/nrf52840dongle_nrf52840-pinctrl.dtsi:22 */
				low-power-enable;      /* in zephyr/boards/nordic/nrf52840dongle/nrf52840dongle_nrf52840-pinctrl.dtsi:25 */
			};

			/* node '/pin-controller/uart0_sleep/group2' defined in zephyr/boards/nordic/nrf52840dongle/nrf52840dongle_nrf52840-pinctrl.dtsi:28 */
			group2 {
				psels = < 0x14 >; /* in zephyr/boards/nordic/nrf52840dongle/nrf52840dongle_nrf52840-pinctrl.dtsi:29 */
				low-power-enable; /* in zephyr/boards/nordic/nrf52840dongle/nrf52840dongle_nrf52840-pinctrl.dtsi:30 */
				bias-pull-up;     /* in zephyr/boards/nordic/nrf52840dongle/nrf52840dongle_nrf52840-pinctrl.dtsi:31 */
			};
		};

		/* node '/pin-controller/i2c0_default' defined in zephyr/boards/nordic/nrf52840dongle/nrf52840dongle_nrf52840-pinctrl.dtsi:35 */
		i2c0_default: i2c0_default {
			phandle = < 0x4 >; /* in zephyr/boards/nordic/nrf52840dongle/nrf52840dongle_nrf52840_common.dtsi:138 */

			/* node '/pin-controller/i2c0_default/group1' defined in zephyr/boards/nordic/nrf52840dongle/nrf52840dongle_nrf52840-pinctrl.dtsi:36 */
			group1 {
				psels = < 0xc00001a >,
				        < 0xb00001b >; /* in zephyr/boards/nordic/nrf52840dongle/nrf52840dongle_nrf52840-pinctrl.dtsi:37 */
			};
		};

		/* node '/pin-controller/i2c0_sleep' defined in zephyr/boards/nordic/nrf52840dongle/nrf52840dongle_nrf52840-pinctrl.dtsi:42 */
		i2c0_sleep: i2c0_sleep {
			phandle = < 0x5 >; /* in zephyr/boards/nordic/nrf52840dongle/nrf52840dongle_nrf52840_common.dtsi:139 */

			/* node '/pin-controller/i2c0_sleep/group1' defined in zephyr/boards/nordic/nrf52840dongle/nrf52840dongle_nrf52840-pinctrl.dtsi:43 */
			group1 {
				psels = < 0xc00001a >,
				        < 0xb00001b >; /* in zephyr/boards/nordic/nrf52840dongle/nrf52840dongle_nrf52840-pinctrl.dtsi:44 */
				low-power-enable;      /* in zephyr/boards/nordic/nrf52840dongle/nrf52840dongle_nrf52840-pinctrl.dtsi:46 */
			};
		};

		/* node '/pin-controller/i2c1_default' defined in zephyr/boards/nordic/nrf52840dongle/nrf52840dongle_nrf52840-pinctrl.dtsi:50 */
		i2c1_default: i2c1_default {
			phandle = < 0x8 >; /* in zephyr/boards/nordic/nrf52840dongle/nrf52840dongle_nrf52840_common.dtsi:147 */

			/* node '/pin-controller/i2c1_default/group1' defined in zephyr/boards/nordic/nrf52840dongle/nrf52840dongle_nrf52840-pinctrl.dtsi:51 */
			group1 {
				psels = < 0xc00001e >,
				        < 0xb00001f >; /* in zephyr/boards/nordic/nrf52840dongle/nrf52840dongle_nrf52840-pinctrl.dtsi:52 */
			};
		};

		/* node '/pin-controller/i2c1_sleep' defined in zephyr/boards/nordic/nrf52840dongle/nrf52840dongle_nrf52840-pinctrl.dtsi:57 */
		i2c1_sleep: i2c1_sleep {
			phandle = < 0x9 >; /* in zephyr/boards/nordic/nrf52840dongle/nrf52840dongle_nrf52840_common.dtsi:148 */

			/* node '/pin-controller/i2c1_sleep/group1' defined in zephyr/boards/nordic/nrf52840dongle/nrf52840dongle_nrf52840-pinctrl.dtsi:58 */
			group1 {
				psels = < 0xc00001e >,
				        < 0xb00001f >; /* in zephyr/boards/nordic/nrf52840dongle/nrf52840dongle_nrf52840-pinctrl.dtsi:59 */
				low-power-enable;      /* in zephyr/boards/nordic/nrf52840dongle/nrf52840dongle_nrf52840-pinctrl.dtsi:61 */
			};
		};

		/* node '/pin-controller/pwm0_default' defined in zephyr/boards/nordic/nrf52840dongle/nrf52840dongle_nrf52840-pinctrl.dtsi:65 */
		pwm0_default: pwm0_default {
			phandle = < 0xc >; /* in zephyr/boards/nordic/nrf52840dongle/nrf52840dongle_nrf52840_common.dtsi:154 */

			/* node '/pin-controller/pwm0_default/group1' defined in zephyr/boards/nordic/nrf52840dongle/nrf52840dongle_nrf52840-pinctrl.dtsi:66 */
			group1 {
				psels = < 0x16000008 >,
				        < 0x17000029 >,
				        < 0x1800000c >; /* in zephyr/boards/nordic/nrf52840dongle/nrf52840dongle_nrf52840-pinctrl.dtsi:67 */
				nordic,invert;          /* in zephyr/boards/nordic/nrf52840dongle/nrf52840dongle_nrf52840-pinctrl.dtsi:70 */
			};
		};

		/* node '/pin-controller/pwm0_sleep' defined in zephyr/boards/nordic/nrf52840dongle/nrf52840dongle_nrf52840-pinctrl.dtsi:74 */
		pwm0_sleep: pwm0_sleep {
			phandle = < 0xd >; /* in zephyr/boards/nordic/nrf52840dongle/nrf52840dongle_nrf52840_common.dtsi:155 */

			/* node '/pin-controller/pwm0_sleep/group1' defined in zephyr/boards/nordic/nrf52840dongle/nrf52840dongle_nrf52840-pinctrl.dtsi:75 */
			group1 {
				psels = < 0x16000008 >,
				        < 0x17000029 >,
				        < 0x1800000c >; /* in zephyr/boards/nordic/nrf52840dongle/nrf52840dongle_nrf52840-pinctrl.dtsi:76 */
				low-power-enable;       /* in zephyr/boards/nordic/nrf52840dongle/nrf52840dongle_nrf52840-pinctrl.dtsi:79 */
			};
		};

		/* node '/pin-controller/spi0_default' defined in zephyr/boards/nordic/nrf52840dongle/nrf52840dongle_nrf52840-pinctrl.dtsi:83 */
		spi0_default: spi0_default {
			phandle = < 0x6 >; /* in zephyr/boards/nordic/nrf52840dongle/nrf52840dongle_nrf52840_common.dtsi:167 */

			/* node '/pin-controller/spi0_default/group1' defined in zephyr/boards/nordic/nrf52840dongle/nrf52840dongle_nrf52840-pinctrl.dtsi:84 */
			group1 {
				psels = < 0x400001b >,
				        < 0x500001a >,
				        < 0x600002a >; /* in zephyr/boards/nordic/nrf52840dongle/nrf52840dongle_nrf52840-pinctrl.dtsi:85 */
			};
		};

		/* node '/pin-controller/spi0_sleep' defined in zephyr/boards/nordic/nrf52840dongle/nrf52840dongle_nrf52840-pinctrl.dtsi:91 */
		spi0_sleep: spi0_sleep {
			phandle = < 0x7 >; /* in zephyr/boards/nordic/nrf52840dongle/nrf52840dongle_nrf52840_common.dtsi:168 */

			/* node '/pin-controller/spi0_sleep/group1' defined in zephyr/boards/nordic/nrf52840dongle/nrf52840dongle_nrf52840-pinctrl.dtsi:92 */
			group1 {
				psels = < 0x400001b >,
				        < 0x500001a >,
				        < 0x600002a >; /* in zephyr/boards/nordic/nrf52840dongle/nrf52840dongle_nrf52840-pinctrl.dtsi:93 */
				low-power-enable;      /* in zephyr/boards/nordic/nrf52840dongle/nrf52840dongle_nrf52840-pinctrl.dtsi:96 */
			};
		};

		/* node '/pin-controller/spi1_default' defined in zephyr/boards/nordic/nrf52840dongle/nrf52840dongle_nrf52840-pinctrl.dtsi:100 */
		spi1_default: spi1_default {
			phandle = < 0xa >; /* in zephyr/boards/nordic/nrf52840dongle/nrf52840dongle_nrf52840_common.dtsi:175 */

			/* node '/pin-controller/spi1_default/group1' defined in zephyr/boards/nordic/nrf52840dongle/nrf52840dongle_nrf52840-pinctrl.dtsi:101 */
			group1 {
				psels = < 0x400001f >,
				        < 0x500001e >,
				        < 0x600002d >; /* in zephyr/boards/nordic/nrf52840dongle/nrf52840dongle_nrf52840-pinctrl.dtsi:102 */
			};
		};

		/* node '/pin-controller/spi1_sleep' defined in zephyr/boards/nordic/nrf52840dongle/nrf52840dongle_nrf52840-pinctrl.dtsi:108 */
		spi1_sleep: spi1_sleep {
			phandle = < 0xb >; /* in zephyr/boards/nordic/nrf52840dongle/nrf52840dongle_nrf52840_common.dtsi:176 */

			/* node '/pin-controller/spi1_sleep/group1' defined in zephyr/boards/nordic/nrf52840dongle/nrf52840dongle_nrf52840-pinctrl.dtsi:109 */
			group1 {
				psels = < 0x400001f >,
				        < 0x500001e >,
				        < 0x600002d >; /* in zephyr/boards/nordic/nrf52840dongle/nrf52840dongle_nrf52840-pinctrl.dtsi:110 */
				low-power-enable;      /* in zephyr/boards/nordic/nrf52840dongle/nrf52840dongle_nrf52840-pinctrl.dtsi:113 */
			};
		};
	};

	/* node '/entropy_bt_hci' defined in zephyr/dts/vendor/nordic/nrf_common.dtsi:34 */
	rng_hci: entropy_bt_hci {
		compatible = "zephyr,bt-hci-entropy"; /* in zephyr/dts/vendor/nordic/nrf_common.dtsi:35 */
		status = "disabled";                  /* in zephyr/dts/vendor/nordic/nrf_common.dtsi:36 */
	};

	/* node '/sw-pwm' defined in zephyr/dts/vendor/nordic/nrf_common.dtsi:39 */
	sw_pwm: sw-pwm {
		compatible = "nordic,nrf-sw-pwm"; /* in zephyr/dts/vendor/nordic/nrf_common.dtsi:40 */
		status = "disabled";              /* in zephyr/dts/vendor/nordic/nrf_common.dtsi:41 */
		generator = < &timer1 >;          /* in zephyr/dts/vendor/nordic/nrf_common.dtsi:42 */
		clock-prescaler = < 0x0 >;        /* in zephyr/dts/vendor/nordic/nrf_common.dtsi:43 */
		#pwm-cells = < 0x3 >;             /* in zephyr/dts/vendor/nordic/nrf_common.dtsi:44 */
	};

	/* node '/cpus' defined in zephyr/dts/arm/nordic/nrf52840.dtsi:19 */
	cpus {
		#address-cells = < 0x1 >; /* in zephyr/dts/arm/nordic/nrf52840.dtsi:20 */
		#size-cells = < 0x0 >;    /* in zephyr/dts/arm/nordic/nrf52840.dtsi:21 */

		/* node '/cpus/cpu@0' defined in zephyr/dts/arm/nordic/nrf52840.dtsi:23 */
		cpu@0 {
			device_type = "cpu";           /* in zephyr/dts/arm/nordic/nrf52840.dtsi:24 */
			compatible = "arm,cortex-m4f"; /* in zephyr/dts/arm/nordic/nrf52840.dtsi:25 */
			reg = < 0x0 >;                 /* in zephyr/dts/arm/nordic/nrf52840.dtsi:26 */
			#address-cells = < 0x1 >;      /* in zephyr/dts/arm/nordic/nrf52840.dtsi:27 */
			#size-cells = < 0x1 >;         /* in zephyr/dts/arm/nordic/nrf52840.dtsi:28 */

			/* node '/cpus/cpu@0/itm@e0000000' defined in zephyr/dts/arm/nordic/nrf52840.dtsi:30 */
			itm: itm@e0000000 {
				compatible = "arm,armv7m-itm";     /* in zephyr/dts/arm/nordic/nrf52840.dtsi:31 */
				reg = < 0xe0000000 0x1000 >;       /* in zephyr/dts/arm/nordic/nrf52840.dtsi:32 */
				swo-ref-frequency = < 0x1e84800 >; /* in zephyr/dts/arm/nordic/nrf52840.dtsi:33 */
			};
		};
	};

	/* node '/clocks' defined in zephyr/dts/arm/nordic/nrf52840.dtsi:38 */
	clocks {

		/* node '/clocks/hfxo' defined in zephyr/dts/arm/nordic/nrf52840.dtsi:39 */
		hfxo: hfxo {
			compatible = "nordic,nrf52-hfxo"; /* in zephyr/dts/arm/nordic/nrf52840.dtsi:40 */
			clock-frequency = < 0x3d09000 >;  /* in zephyr/dts/arm/nordic/nrf52840.dtsi:41 */
			startup-time-us = < 0x578 >;      /* in zephyr/dts/arm/nordic/nrf52840.dtsi:42 */
			#clock-cells = < 0x0 >;           /* in zephyr/dts/arm/nordic/nrf52840.dtsi:43 */
		};
	};

	/* node '/leds' defined in zephyr/boards/nordic/nrf52840dongle/nrf52840dongle_nrf52840_common.dtsi:24 */
	leds {
		compatible = "gpio-leds"; /* in zephyr/boards/nordic/nrf52840dongle/nrf52840dongle_nrf52840_common.dtsi:25 */

		/* node '/leds/led_0' defined in zephyr/boards/nordic/nrf52840dongle/nrf52840dongle_nrf52840_common.dtsi:27 */
		led0_green: led_0 {
			gpios = < &gpio0 0x6 0x1 >; /* in zephyr/boards/nordic/nrf52840dongle/nrf52840dongle_nrf52840_common.dtsi:28 */
			label = "Green LED 0";      /* in zephyr/boards/nordic/nrf52840dongle/nrf52840dongle_nrf52840_common.dtsi:29 */
		};

		/* node '/leds/led_1' defined in zephyr/boards/nordic/nrf52840dongle/nrf52840dongle_nrf52840_common.dtsi:32 */
		led1_red: led_1 {
			gpios = < &gpio0 0x8 0x1 >; /* in zephyr/boards/nordic/nrf52840dongle/nrf52840dongle_nrf52840_common.dtsi:33 */
			label = "Red LED 1";        /* in zephyr/boards/nordic/nrf52840dongle/nrf52840dongle_nrf52840_common.dtsi:34 */
		};

		/* node '/leds/led_2' defined in zephyr/boards/nordic/nrf52840dongle/nrf52840dongle_nrf52840_common.dtsi:37 */
		led1_green: led_2 {
			gpios = < &gpio1 0x9 0x1 >; /* in zephyr/boards/nordic/nrf52840dongle/nrf52840dongle_nrf52840_common.dtsi:38 */
			label = "Green LED 1";      /* in zephyr/boards/nordic/nrf52840dongle/nrf52840dongle_nrf52840_common.dtsi:39 */
		};

		/* node '/leds/led_3' defined in zephyr/boards/nordic/nrf52840dongle/nrf52840dongle_nrf52840_common.dtsi:42 */
		led1_blue: led_3 {
			gpios = < &gpio0 0xc 0x1 >; /* in zephyr/boards/nordic/nrf52840dongle/nrf52840dongle_nrf52840_common.dtsi:43 */
			label = "Blue LED 1";       /* in zephyr/boards/nordic/nrf52840dongle/nrf52840dongle_nrf52840_common.dtsi:44 */
		};
	};

	/* node '/pwmleds' defined in zephyr/boards/nordic/nrf52840dongle/nrf52840dongle_nrf52840_common.dtsi:48 */
	pwmleds {
		compatible = "pwm-leds"; /* in zephyr/boards/nordic/nrf52840dongle/nrf52840dongle_nrf52840_common.dtsi:49 */

		/* node '/pwmleds/pwm_led_0' defined in zephyr/boards/nordic/nrf52840dongle/nrf52840dongle_nrf52840_common.dtsi:51 */
		red_pwm_led: pwm_led_0 {
			pwms = < &pwm0 0x0 0x1312d00 0x1 >; /* in zephyr/boards/nordic/nrf52840dongle/nrf52840dongle_nrf52840_common.dtsi:52 */
		};

		/* node '/pwmleds/pwm_led_1' defined in zephyr/boards/nordic/nrf52840dongle/nrf52840dongle_nrf52840_common.dtsi:55 */
		green_pwm_led: pwm_led_1 {
			pwms = < &pwm0 0x1 0x1312d00 0x1 >; /* in zephyr/boards/nordic/nrf52840dongle/nrf52840dongle_nrf52840_common.dtsi:56 */
		};

		/* node '/pwmleds/pwm_led_2' defined in zephyr/boards/nordic/nrf52840dongle/nrf52840dongle_nrf52840_common.dtsi:59 */
		blue_pwm_led: pwm_led_2 {
			pwms = < &pwm0 0x2 0x1312d00 0x1 >; /* in zephyr/boards/nordic/nrf52840dongle/nrf52840dongle_nrf52840_common.dtsi:60 */
		};
	};

	/* node '/buttons' defined in zephyr/boards/nordic/nrf52840dongle/nrf52840dongle_nrf52840_common.dtsi:64 */
	buttons {
		compatible = "gpio-keys"; /* in zephyr/boards/nordic/nrf52840dongle/nrf52840dongle_nrf52840_common.dtsi:65 */

		/* node '/buttons/button_0' defined in zephyr/boards/nordic/nrf52840dongle/nrf52840dongle_nrf52840_common.dtsi:67 */
		button0: button_0 {
			gpios = < &gpio1 0x6 0x11 >;    /* in zephyr/boards/nordic/nrf52840dongle/nrf52840dongle_nrf52840_common.dtsi:68 */
			label = "Push button switch 0"; /* in zephyr/boards/nordic/nrf52840dongle/nrf52840dongle_nrf52840_common.dtsi:69 */
			zephyr,code = < 0xb >;          /* in zephyr/boards/nordic/nrf52840dongle/nrf52840dongle_nrf52840_common.dtsi:70 */
		};
	};
};
